# STM32WL5Mxx register map
File version: 1.0
Registers are 32-bit, read-write, reset 0x0 unless marked. A register's access mark holds for its fields unless they carry their own. Offsets are from the block's base; [hi:lo] are bit positions; {n}, {i} and the like mark numbered series.

## IPCC — Inter-Processor Communication
Base 0x58000C00
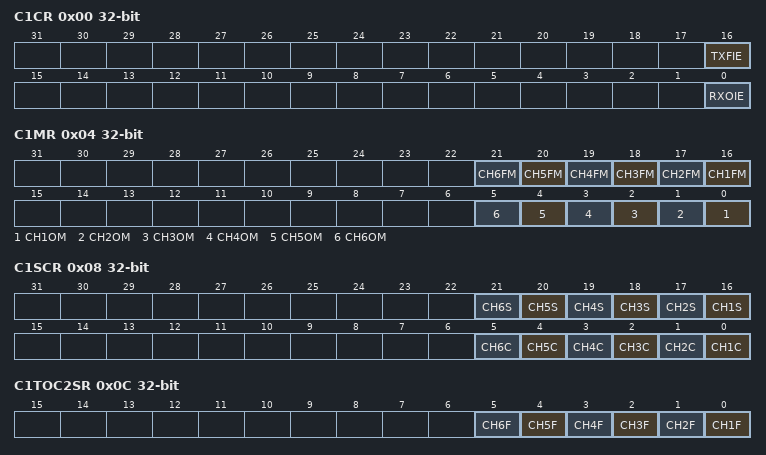
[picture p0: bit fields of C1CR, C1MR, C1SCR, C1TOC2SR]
0x00 C1CR — Inter-Processor Communication: C1 control register
  [16] TXFIE — Processor M4 Transmit channel free interrupt enable
  [0] RXOIE — Processor M4 Receive channel occupied interrupt enable
0x04 C1MR — Inter-Processor Communication: C1 mask register
  [n+15] CH{n}FM (n=1..6) — M4 Transmit Channel{n} free interrupt mask
  [n-1] CH{n}OM (n=1..6) — M4 Channel{n} occupied interrupt mask
0x08 C1SCR — Inter-Processor Communication: C1 status set clear register
  [n+15] CH{n}S (n=1..6) — M4 transmit Channel{n} status set
  [n-1] CH{n}C (n=1..6) — M4 receive Channel{n} status clear
0x0C C1TOC2SR — Inter-Processor Communication: C1 to processor M4 status register
  [n-1] CH{n}F (n=1..6) — M4 transmit to M4 receive Channel{n} status flag before masking
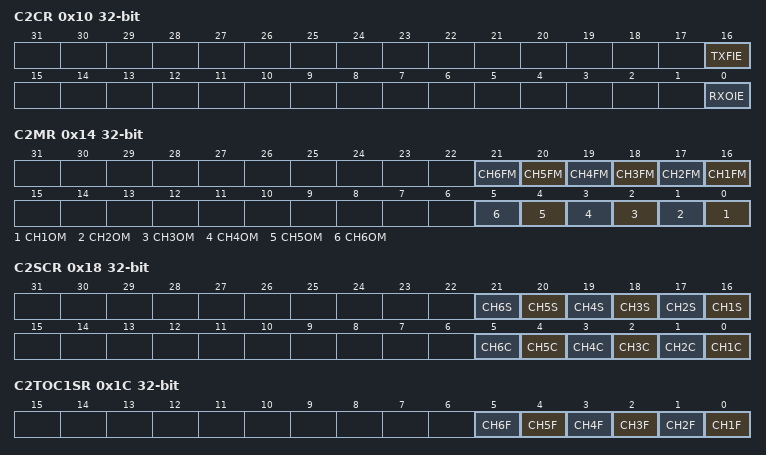
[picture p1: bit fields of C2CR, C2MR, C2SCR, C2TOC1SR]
0x10 C2CR — Inter-Processor Communication: C2 control register
  [16] TXFIE — Processor M0+ Transmit channel free interrupt enable
  [0] RXOIE — Processor M0+ Receive channel occupied interrupt enable
0x14 C2MR — Inter-Processor Communication: C2 mask register
  [n+15] CH{n}FM (n=1..6) — M0+ Transmit Channel{n} free interrupt mask
  [n-1] CH{n}OM (n=1..6) — M0+ Channel{n} occupied interrupt mask
0x18 C2SCR — Inter-Processor Communication: C2 status set clear register
  [n+15] CH{n}S (n=1..6) — M0+ transmit Channel{n} status set
  [n-1] CH{n}C (n=1..6) — M0+ receive Channel{n} status clear
0x1C C2TOC1SR — Inter-Processor Communication: C2 to processor M4 status register
  [n-1] CH{n}F (n=1..6) — M0+ transmit to M0 receive Channel{n} status flag before masking

## RNG
Base 0x58001000
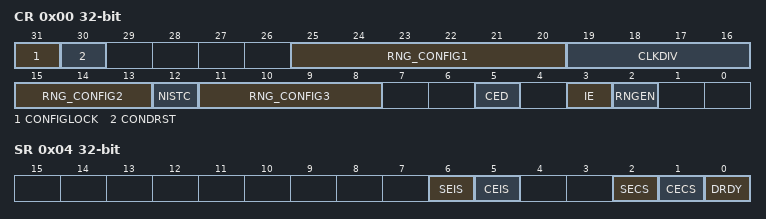
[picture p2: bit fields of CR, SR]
0x00 CR — RNG control register
  [31] CONFIGLOCK
  [30] CONDRST
  [25:20] RNG_CONFIG1
  [19:16] CLKDIV
    0=BY_1 (No clock division); 1=BY_2 (2 RNG clock cycles per internal RNG clock); 2=BY_4 (4 RNG clock cycles per internal RNG clock); 3=BY_8 (8 RNG clock cycles per internal RNG clock); 4=BY_16 (16 RNG clock cycles per internal RNG clock); 5=BY_32 (32 RNG clock cycles per internal RNG clock); 6=BY_64 (64 RNG clock cycles per internal RNG clock); 7=BY_128 (128 RNG clock cycles per internal RNG clock); 8=BY_256 (256 RNG clock cycles per internal RNG clock); 9=BY_512 (512 RNG clock cycles per internal RNG clock); 10=BY_1024 (1024 RNG clock cycles per internal RNG clock); 11=BY_2048 (2048 RNG clock cycles per internal RNG clock); 12=BY_4096 (4096 RNG clock cycles per internal RNG clock); 13=BY_8192 (8192 RNG clock cycles per internal RNG clock); 14=BY_16384 (16384 RNG clock cycles per internal RNG clock); 15=BY_32768 (32768 RNG clock cycles per internal RNG clock)
  [15:13] RNG_CONFIG2
  [12] NISTC
  [11:8] RNG_CONFIG3
  [5] CED
  [3] IE
  [2] RNGEN
0x04 SR — RNG status register
  [6] SEIS, [5] CEIS, [2] SECS, [1] CECS, [0] DRDY
0x08 DR — RNG data register
  [31:0] RNDATA
0x10 HTCR — RNG health test control register
  [31:0] HTCFG

## HSEM — HW Semaphore HSEM
Base 0x58001400
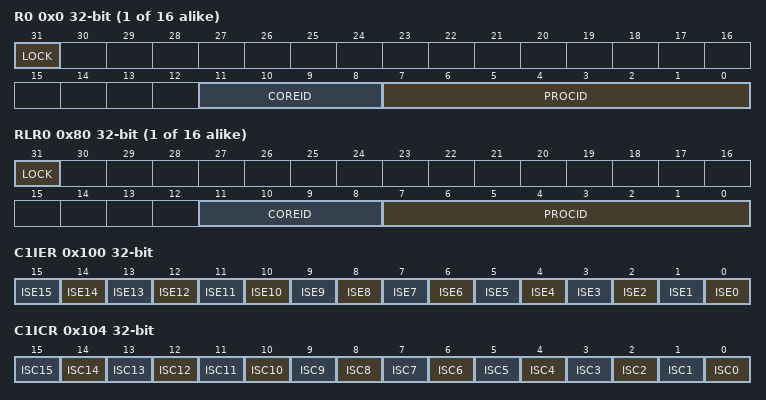
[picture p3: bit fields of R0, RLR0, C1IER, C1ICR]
{0x0+4i} R{i} (i=0..15) — HSEM 2-step write lock and read back registers
  [31] LOCK — Lock indication
  [11:8] COREID — Semaphore CoreID
    0=NONE; 4=CPU1; 8=CPU2
  [7:0] PROCID — Semaphore ProcessID
{0x80+4i} RLR{i} (i=0..15) — HSEM 1-step read lock registers
  [31] LOCK — Lock indication
  [11:8] COREID — Semaphore CoreID
  [7:0] PROCID — Semaphore ProcessID
0x100 C1IER — HSEM CPU1 interrupt enable register
  [n] ISE{n} (n=0..15) — semaphore {n} CPU1 interrupt enable bit
0x104 C1ICR — HSEM CPU1 interrupt clear register
  [n] ISC{n} (n=0..15) — semaphore {n} CPU1 interrupt clear bit
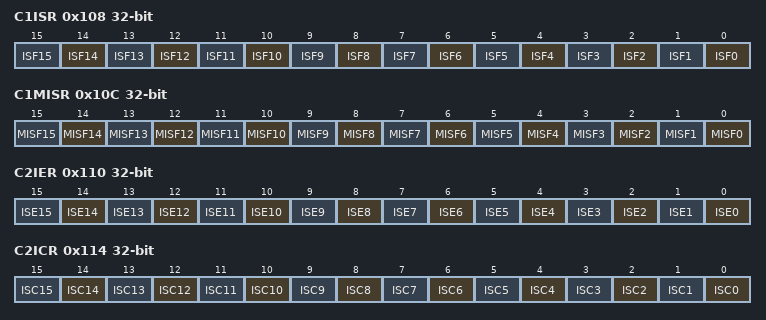
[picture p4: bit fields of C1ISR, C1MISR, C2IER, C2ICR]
0x108 C1ISR — HSEM CPU1 interrupt status register
  [n] ISF{n} (n=0..15) — semaphore {n} CPU1 interrupt status bit
0x10C C1MISR — HSEM CPU1 masked interrupt status register
  [n] MISF{n} (n=0..15) — semaphore {n} CPU1 interrupt masked status bit
0x110 C2IER — HSEM CPU2 interrupt enable register
  [n] ISE{n} (n=0..15) — semaphore {n} CPU2 interrupt enable bit
0x114 C2ICR — HSEM CPU2 interrupt clear register
  [n] ISC{n} (n=0..15) — semaphore {n} CPU2 interrupt clear bit
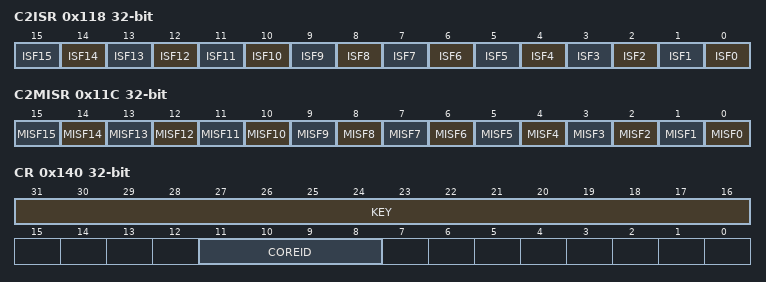
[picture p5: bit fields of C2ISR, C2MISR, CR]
0x118 C2ISR — HSEM CPU2 interrupt status register
  [n] ISF{n} (n=0..15) — semaphore {n} CPU2 interrupt status bit
0x11C C2MISR — HSEM CPU2 masked interrupt status register
  [n] MISF{n} (n=0..15) — semaphore {n} CPU2 interrupt masked status bit
0x140 CR — HSEM Semaphore clear register
  [31:16] KEY — semaphores clear key
  [11:8] COREID — CoreID of semaphores to be cleared
0x144 KEYR — HSEM Semaphore clear key register
  [31:16] KEY — semaphores clear key
